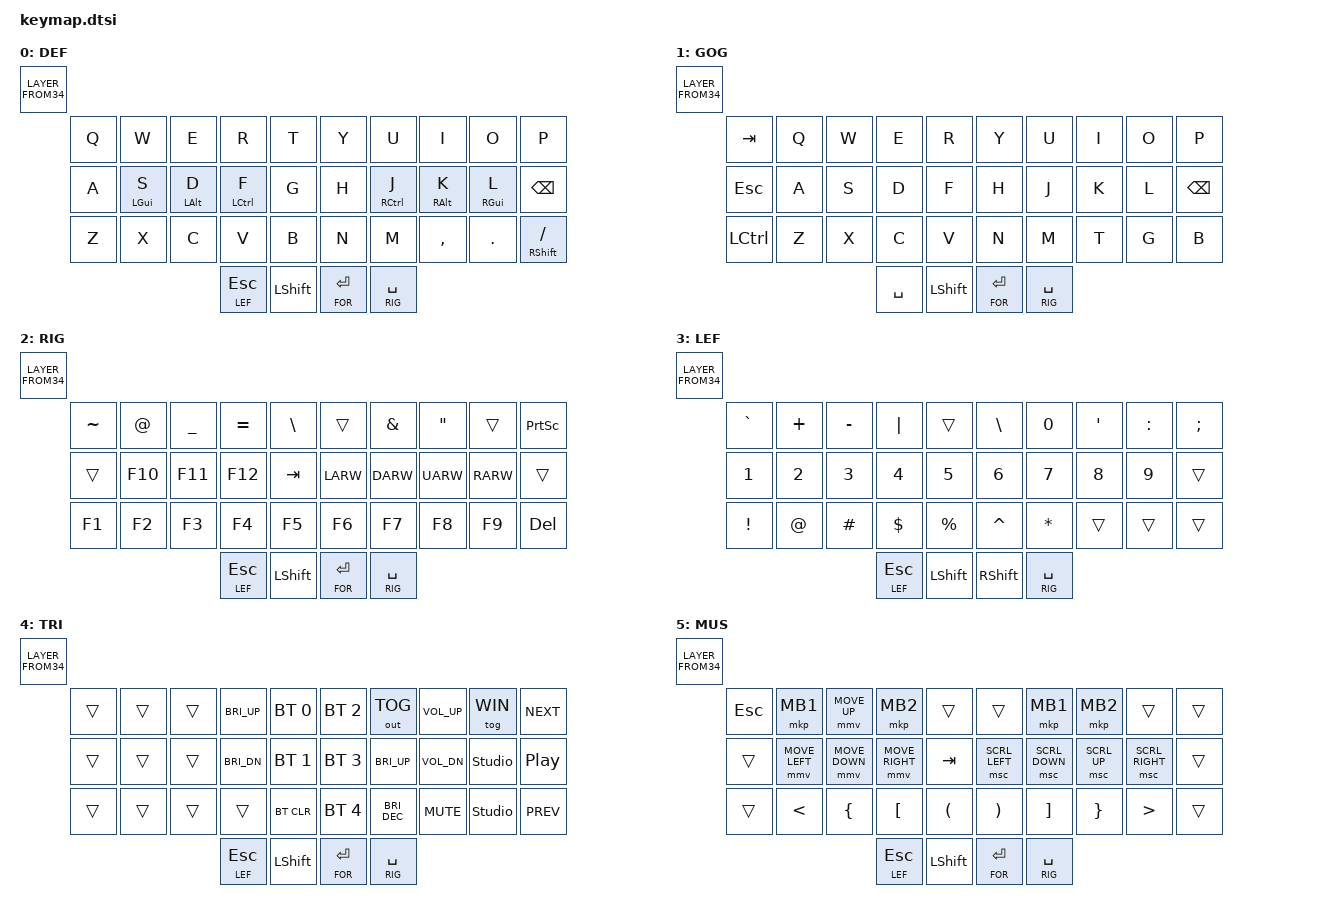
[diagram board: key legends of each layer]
/*
 * Copyright (c) 2020 The ZMK Contributors
 *
 * SPDX-License-Identifier: MIT
 */

#include <dt-bindings/zmk/bt.h>
#include <dt-bindings/zmk/keys.h>
#include <dt-bindings/zmk/mouse.h>
#include <dt-bindings/zmk/outputs.h>

#ifndef KEYMAP_DRAWER
#include "include/keys_de.h"
#endif

#define MAC 0
#define WIN 1
#define RIG 2
#define LEF 3
#define TRI 4
#define FOR 5

#define CT(KEY) &mt LC(KEY) KEY

#define MEH     LC(LS(LALT))
#define HYPER   LC(LS(LA(LGUI)))

#define U_RDO   LC(DE_Y)
#define U_PST   LC(V)
#define U_PST_P LS(LC(V))
#define U_CPY   LC(C)
#define U_CPY_P LS(LC(C))
#define U_CUT   LC(X)
#define U_UND   LC(DE_Z)

#include "include/keypos.h"
#include "behaviors.dtsi"
#include "combos.dtsi"
#include "macros.dtsi"
#include "mouse.dtsi"

/ {

    behaviors {
        ht: hold_tap {
            label = "hold_tap";
            compatible = "zmk,behavior-hold-tap";
            #binding-cells = <2>;
            flavor = "tap-preferred";
            tapping-term-ms = <220>;
            quick-tap-ms = <150>;
            global-quick-tap;
            bindings = <&kp>, <&kp>;
        };
    };


    conditional_layers {
        compatible = "zmk,conditional-layers";

        tri_layer  {
            if-layers = <RIG LEF>;
            then-layer = <TRI>;
        };
    };

    keymap {
        compatible = "zmk,keymap";

        default_layer {
            display-name = "DEF";
            bindings = <LAYER_FROM34( \
/* // ╭─────────────┬─────────────┬─────────────┬──────────────┬──────────────╮   ╭─────────────┬─────────────┬───────────────┬─────────────────┬─────────────╮ */
/*     &kp V,        &kp W,        &kp F,        &kp P,         &kp B,             &kp J,        &kp L,        &kp U,          &kp DE_Y,         &td_sqt_dqt, \ */
/* // ├─────────────┼─────────────┼─────────────┼──────────────┼──────────────┤   ├─────────────┼─────────────┼───────────────┼─────────────────┼─────────────┤ */
/*     &hml LGUI R,  &hml LALT S,  &hcl LCTRL T, &hsl LSHIFT H, &kp K,             &kp X,        &hsr RSHFT N, &hcr_a RCTRL 0, &hmr LALT I,      &hmr LGUI O, \ */
/* // ├─────────────┼─────────────┼─────────────┼──────────────┼──────────────┤   ├─────────────┼─────────────┼───────────────┼─────────────────┼─────────────┤ */
/*     &kp DE_Z,     &hml RALT C,  &kp G,        &kp D,         &kp Q,             &key_repeat,  &kp M,        &ad_comma,      &hmr RALT DE_DOT, &qexcl,      \ */
/* // ╰─────────────┴─────────────┴─────────────┼──────────────┼──────────────┤   ├─────────────┼─────────────┼───────────────┴─────────────────┴─────────────╯ */
/*                                               &bspc_del,     &lt NAV SPACE,     &lt NUM E,    &kp RET      \ */
/* //                                           ╰──────────────┴──────────────╯   ╰─────────────┴─────────────╯ */
            //╭──────────┬──────────┬──────────┬──────────┬──────────╮   ╭──────────┬──────────┬──────────┬──────────┬──────────╮
            //│  Q       │  W       │  E       │  R       │  T       │   │  Y       │  U       │  I       │  O       │  P       │
                &kp Q,      &kp W,     &kp E,     &kp R,     &kp T,        &kp Y,      &kp U,      &kp I,    &kp O,   &kp P, \
            //├──────────┼──────────┼──────────┼──────────┼──────────┤   ├──────────┼──────────┼──────────┼──────────┼──────────┤
            //│  A       │  S       │  D       │  F       │  G       │   │  H       │  J       │  K       │  L       │   BSPC   │
                &kp A,     &ht LGUI S, &ht LALT D, &ht LCTRL F, &kp G,  &kp H,  &ht RCTRL J, &ht RALT K, &ht RGUI L, &kp BSPC, \
            //├──────────┼──────────┼──────────┼──────────┼──────────┤   ├──────────┼──────────┼──────────┼──────────┼──────────┤
            //│  Z       │  X       │  C       │  V       │  B       │   │  N       │  M       │ , <      │ . >      │   ? /    │
                &kp Z,      &kp X,      &kp C,     &kp V,     &kp B,         &kp N,     &kp M,     &kp COMMA, &kp DOT,   &ht RSHFT SLASH, \
            //╰──────────┴──────────┴──────────┼──────────┼──────────┤   ├──────────┼──────────┼──────────┴──────────┴──────────╯
                                              &lt LEF ESC,    &kp LSHFT,    &lt FOR ENTER, &lt RIG SPACE \
            //                                 ╰──────────┴──────────╯   ╰──────────┴──────────╯
            )>;
        };

        gaming_layer {
            display-name = "GOG";
            bindings = <LAYER_FROM34( \
            //╭──────────┬──────────┬──────────┬──────────┬──────────╮   ╭──────────┬──────────┬──────────┬──────────┬──────────╮
            //│  TAB     │  Q       │  W       │  E       │  R       │   │  Y       │  U       │  I       │  O       │  P       │
                &kp TAB,    &kp Q,     &kp W,     &kp E,     &kp R,         &kp Y,     &kp U,     &kp I,     &kp O,     &kp P, \
            //├──────────┼──────────┼──────────┼──────────┼──────────┤   ├──────────┼──────────┼──────────┼──────────┼──────────┤
            //│  ESC     │  A       │  S       │  D       │  F       │   │  H       │  J       │  K       │  L       │   BSPC   │
                &kp ESC,    &kp A,     &kp S,      &kp D,    &kp F,         &kp H,     &kp J,     &kp K,     &kp L,     &kp BSPC, \
            //├──────────┼──────────┼──────────┼──────────┼──────────┤   ├──────────┼──────────┼──────────┼──────────┼──────────┤
            //│  CTRL    │  Z       │  X       │  C       │  V       │   │  N       │  M       │  T       │  G       │   B      │
                &kp LCTRL,  &kp Z,     &kp X,     &kp C,     &kp V,         &kp N,     &kp M,     &kp T,     &kp G,     &kp B, \
            //╰──────────┴──────────┴──────────┼──────────┼──────────┤   ├──────────┼──────────┼──────────┴──────────┴──────────╯
                                               &kp SPACE,  &kp LSHFT,      &lt FOR ENTER, &lt RIG SPACE \
            //                                 ╰──────────┴──────────╯   ╰──────────┴──────────╯
	    )>;
        };

        right_layer {
            display-name = "RIG";
            bindings = <LAYER_FROM34( \
        //╭──────────┬──────────┬──────────┬──────────┬──────────╮   ╭──────────┬──────────┬──────────┬──────────┬──────────╮
        //│ ~        │ @        │ _        │ =        │  \       │   │          │  &       │  "       │          │   PSCRN  │
            &kp TILDE, &kp AT,    &kp UNDER,  &kp EQUAL,  &kp BSLH,        &trans,    &kp AMPS,  &kp DQT,  &trans,     &kp PSCRN, \
        //├──────────┼──────────┼──────────┼──────────┼──────────┤   ├──────────┼──────────┼──────────┼──────────┼──────────┤
        //│          │          │          │          │ TAB      |   |  LEFT    │   DOWN   │   UP     │   RIGHT  │          │
            &trans,   &kp F10,    &kp F11,   &kp F12,    &kp TAB,        &kp LARW,   &kp DARW,  &kp UARW,  &kp RARW,  &trans, \
        //├──────────┼──────────┼──────────┼──────────┼──────────┤   ├──────────┼──────────┼──────────┼──────────┼──────────┤
        //│          │          │          │          │          │   │          │          │          │          │   DEL    │
            &kp F1,   &kp F2,    &kp F3,     &kp F4,     &kp F5,          &kp F6,    &kp F7,  &kp F8,      &kp F9,    &kp DEL, \
        //╰──────────┴──────────┴──────────┼──────────┼──────────┤   ├──────────┼──────────┼──────────┴──────────┴──────────╯
                                        &lt LEF ESC,   &kp LSHFT,      &lt FOR ENTER, &lt RIG SPACE \
        //                                 ╰──────────┴──────────╯   ╰──────────┴──────────╯
            )>;
        };

        left_layer {
            display-name = "LEF";
            bindings = <LAYER_FROM34( \
        //╭──────────┬──────────┬──────────┬──────────┬──────────╮   ╭──────────┬──────────┬──────────┬──────────┬──────────╮
        //│  `       │  +       │  -       │  |       │          │   │   \      │ 0        │  '       │  :       │   ;      │
            &kp GRAVE,  &kp PLUS, &kp MINUS, &kp PIPE, &trans,        &kp BSLH,  &kp N0,    &kp SQT, &kp COLON,  &kp SEMI, \
        //├──────────┼──────────┼──────────┼──────────┼──────────┤   ├──────────┼──────────┼──────────┼──────────┼──────────┤
        //│  1       │  2       │  3       │  4       │  5       │   │   6      │  7       │  8       │     9    │          │
            &kp N1,   &kp N2,    &kp N3,    &kp N4,    &kp N5,         &kp N6,    &kp N7,    &kp N8,    &kp N9,     &trans, \
        //├──────────┼──────────┼──────────┼──────────┼──────────┤   ├──────────┼──────────┼──────────┼──────────┼──────────┤
        //│  !       │  @       │  #       │  $       │  %       │   │   ^      │  *       │          │          │          │
            &kp EXCL,  &kp AT,   &kp HASH,  &kp DLLR,   &kp PRCNT,     &kp CARET, &kp STAR,  &trans,    &trans,   &trans, \
        //╰──────────┴──────────┴──────────┼──────────┼──────────┤   ├──────────┼──────────┼──────────┴──────────┴──────────╯
                                        &lt LEF ESC,   &kp LSHFT,       &kp RSHFT, &lt RIG SPACE \
        //                                  ╰───────────┴──────────╯   ╰──────────┴────────────╯
	    )>;
        }; 

        tri_layer {
            display-name = "TRI";
            bindings = <LAYER_FROM34( \
        //╭──────────┬──────────┬──────────┬───────────┬────────────╮   ╭────────────┬────────────┬──────────┬───────────┬──────────╮
        //│          │          │          │  BRI_UP   │ PROFILE 0  │   │ PROFILE 2  │ TOGGLEOUT  │   VOL +  │ WINDOWS   │ NEXTSONG │
            &trans,    &trans,    &trans,   &kp C_BRI_UP, &bt BT_SEL 0,   &bt BT_SEL 2,  &out OUT_TOG, &kp C_VOL_UP,  &tog WIN,  &kp C_NEXT, \
        //├──────────┼──────────┼──────────┼───────────┼────────────┤   ├────────────┼────────────┼──────────┼───────────┼──────────┤
        //│          │          │          │  BRI_DOWN │ PROFILE 1  │   │ PROFILE 3  │ INC BRIGHT │  VOL -   │           │PAUSEMUSIC│
            &trans,     &trans,     &trans, &kp C_BRI_DN, &bt BT_SEL 1,   &bt BT_SEL 3,  &kp C_BRI_UP,  &kp C_VOL_DN, &studio_unlock,  &kp C_PP, \
        //├──────────┼──────────┼──────────┼───────────┼────────────┤   ├────────────┼────────────┼──────────┼───────────┼──────────┤
        //│          │          │          │           │  CLEAR BT  │   │ PROFILE 4  │ DEC BRIGHT │  MUTE    |           │ PREVSONG │
            &trans,     &trans,     &trans,    &trans,       &bt BT_CLR,      &bt BT_SEL 4,  &kp C_BRI_DEC,  &kp C_MUTE,  &studio_unlock,  &kp C_PREV, \
        //╰──────────┴──────────┴──────────┼───────────┼────────────┤   ├────────────┼────────────┼──────────┴───────────┴──────────╯
                                        &lt LEF ESC,    &kp LSHFT,       &lt FOR ENTER,  &lt RIG SPACE \
        //                                   ╰───────────┴──────────╯   ╰──────────┴────────────╯ 
            )>;
        };

        four_layer {
            display-name = "MUS";
            bindings = <LAYER_FROM34( \
        //╭──────────┬──────────┬──────────┬───────────┬────────────╮   ╭────────────┬────────────┬──────────┬───────────┬──────────╮
        //│  ESC     │          │          │           │            │   │            │            │          │           │          │
            &kp ESC,  &mkp MB1, &mmv MOVE_UP,   &mkp MB2,    &trans,      &trans,       &mkp MB1,  &mkp MB2,   &trans,  &trans, \
        //├──────────┼──────────┼──────────┼───────────┼────────────┤   ├────────────┼────────────┼──────────┼───────────┼──────────┤
        //│          │          │          │           │    TAB     │   │            │            │          │           │          │
    &trans, &mmv MOVE_LEFT,  &mmv MOVE_DOWN,  &mmv MOVE_RIGHT,  &kp TAB,      &msc SCRL_LEFT,  &msc SCRL_DOWN,  &msc SCRL_UP,   &msc SCRL_RIGHT,  &trans, \
        //├──────────┼──────────┼──────────┼───────────┼────────────┤   ├────────────┼────────────┼──────────┼───────────┼──────────┤
        //│          │ <        │ {        │ [         │   (        │   │ )          │ ]          │ }        | >         │          │
        &trans,    &kp LT,   &kp LBRC,   &kp LBKT,    &kp LPAR,          &kp RPAR,     &kp RBKT,   &kp RBRC,  &kp GT,      &trans, \
        //╰──────────┴──────────┴──────────┼───────────┼────────────┤   ├────────────┼────────────┼──────────┴───────────┴──────────╯
                                        &lt LEF ESC,   &kp LSHFT,      &lt FOR ENTER, &lt RIG SPACE \
        //                                   ╰───────────┴──────────╯   ╰──────────┴────────────╯
            )>;
        };

        extra1 {
            status = "reserved";
        };

        extra2 {
            status = "reserved";
        };
    };
};
